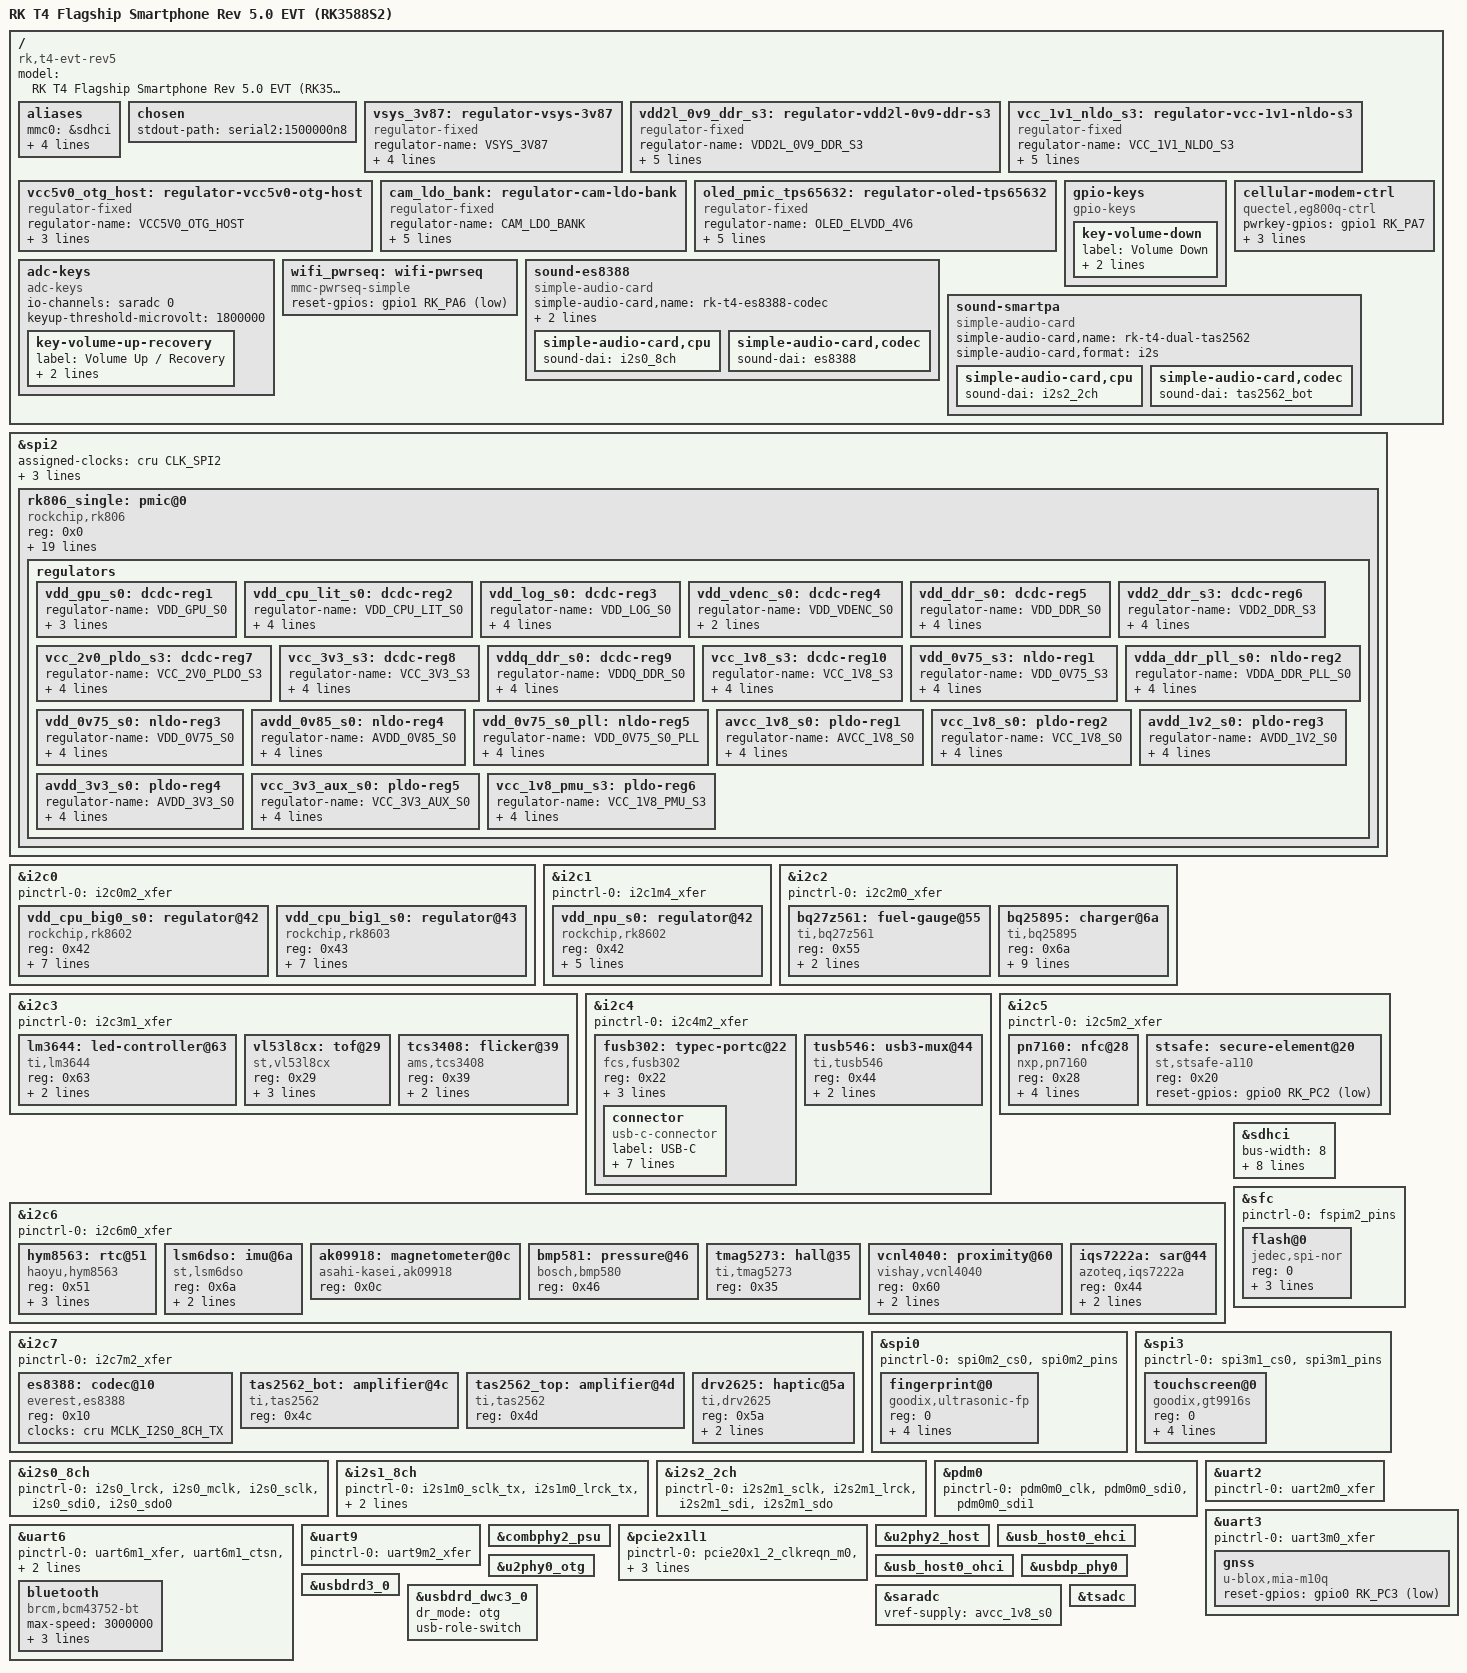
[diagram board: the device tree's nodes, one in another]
// SPDX-License-Identifier: (GPL-2.0+ OR MIT)
/*
 * RK T4 Flagship Smartphone — Rev 5.0 True EVT Linux Device Tree
 * Auto-generated directly from hardware/rk_t4_netlist.json + rk3588s2_1253.json
 * ZERO manual pin guessing: every ball, GPIO bank/pin, mux group, and I2C address
 * is locked 1:1 to the DRC-clean 14L Mainboard + 8L RF Mezzanine PCBs.
 *
 * SoC: Rockchip RK3588S2 (FCCSP1253L, 16GB LPDDR5X-6400, 256GB eMMC 5.1 HS400)
 */

/dts-v1/;

#include <dt-bindings/gpio/gpio.h>
#include <dt-bindings/input/input.h>
#include <dt-bindings/interrupt-controller/irq.h>
#include <dt-bindings/pinctrl/rockchip.h>
#include <dt-bindings/usb/pd.h>
#include "rk3588s.dtsi"

/ {
	model = "RK T4 Flagship Smartphone Rev 5.0 EVT (RK3588S2)";
	compatible = "rk,t4-evt-rev5", "rockchip,rk3588s";

	aliases {
		mmc0 = &sdhci;
		serial2 = &uart2;
		serial3 = &uart3;
		serial6 = &uart6;
		serial9 = &uart9;
	};

	chosen {
		stdout-path = "serial2:1500000n8"; /* U101.AH39 [I2S1_MCLK_M1/JTAG_TCK_M2/I2C1_SCL_M0/UART2_TX_M0/PCIE20X1_1_CLKREQN_M0/GPIO0_B5_d] / U101.AH40 [I2S1_SCLK_TX_M1/JTAG_TMS_M2/I2C1_SDA_M0/UART2_RX_M0/PCIE20X1_1_WAKEN_M0/GPIO0_B6_d] */
	};

	/* Main Battery System Supply (6000mAh 1S2P Si-C via TI BQ25895RTWR NVDC) */
	vsys_3v87: regulator-vsys-3v87 {
		compatible = "regulator-fixed";
		regulator-name = "VSYS_3V87";
		regulator-always-on;
		regulator-boot-on;
		regulator-min-microvolt = <3870000>;
		regulator-max-microvolt = <3870000>;
	};

	/* Dedicated Silergy SY8089AAAC U211 (R211=49.9K / R212=100K -> 0.8994V LPDDR5X VDD2L) */
	vdd2l_0v9_ddr_s3: regulator-vdd2l-0v9-ddr-s3 {
		compatible = "regulator-fixed";
		regulator-name = "VDD2L_0V9_DDR_S3";
		regulator-always-on;
		regulator-boot-on;
		regulator-min-microvolt = <900000>;
		regulator-max-microvolt = <900000>;
		vin-supply = <&vsys_3v87>;
	};

	/* Dedicated Silergy SY8089AAAC U212 (R213=100K / R214=120K -> 1.100V RK806 NLDO Pre-Reg) */
	vcc_1v1_nldo_s3: regulator-vcc-1v1-nldo-s3 {
		compatible = "regulator-fixed";
		regulator-name = "VCC_1V1_NLDO_S3";
		regulator-always-on;
		regulator-boot-on;
		regulator-min-microvolt = <1100000>;
		regulator-max-microvolt = <1100000>;
		vin-supply = <&vsys_3v87>;
	};

	/* TI TPS61022RWUR U210 (R235=732K / R236=100K -> 4.992V USB-C OTG/VCONN Boost) */
	vcc5v0_otg_host: regulator-vcc5v0-otg-host {
		compatible = "regulator-fixed";
		regulator-name = "VCC5V0_OTG_HOST";
		regulator-min-microvolt = <5000000>;
		regulator-max-microvolt = <5000000>;
		vin-supply = <&vsys_3v87>;
	};

	/* SG Micro SGM2036 Discrete Camera RF LDO Bank (U401A..G, U403A..E) */
	cam_ldo_bank: regulator-cam-ldo-bank {
		compatible = "regulator-fixed";
		regulator-name = "CAM_LDO_BANK";
		regulator-min-microvolt = <2800000>;
		regulator-max-microvolt = <2800000>;
		enable-active-high;
		gpio = <&gpio4 RK_PB1 GPIO_ACTIVE_HIGH>; /* U101.AU22 (GPIO4_B1_u) */
		vin-supply = <&vsys_3v87>;
	};

	/* TI TPS65632RTER U501 Triple AMOLED PMIC (+4.6V / -4.0V / +7.7V, SWIRE CTRL) */
	oled_pmic_tps65632: regulator-oled-tps65632 {
		compatible = "regulator-fixed";
		regulator-name = "OLED_ELVDD_4V6";
		regulator-min-microvolt = <4600000>;
		regulator-max-microvolt = <4600000>;
		enable-active-high;
		gpio = <&gpio3 RK_PC1 GPIO_ACTIVE_HIGH>; /* U101.AW38 (GPIO3_C1_d) */
		/* SWIRE single-wire brightness/ELVSS control: U101.AV37 [ETH1_REFCLKO_25M/MIPI_CAMERA1_CLK_M1/I2C4_SCL_M0/GPIO3_A6_d] */
		vin-supply = <&vsys_3v87>;
	};

	/* Side Tactile Keys (Vol- GPIO + Vol+ Recovery SARADC_IN0) */
	gpio-keys {
		compatible = "gpio-keys";
		key-volume-down {
			label = "Volume Down";
			linux,code = <KEY_VOLUMEDOWN>;
			gpios = <&gpio4 RK_PD3 GPIO_ACTIVE_LOW>; /* U101.AT1 (GPIO4_D3_u) */
		};
	};

	adc-keys {
		compatible = "adc-keys";
		io-channels = <&saradc 0>; /* U101.AW15 [SARADC_IN0_BOOT] */
		io-channel-names = "buttons";
		keyup-threshold-microvolt = <1800000>;
		key-volume-up-recovery {
			label = "Volume Up / Recovery";
			linux,code = <KEY_VOLUMEUP>;
			press-threshold-microvolt = <17000>;
		};
	};

	/* Wi-Fi 6E AP6275P Power Sequence (3.3V VBAT <= 3.8V max!) */
	wifi_pwrseq: wifi-pwrseq {
		compatible = "mmc-pwrseq-simple";
		reset-gpios = <&gpio1 RK_PA6 GPIO_ACTIVE_LOW>; /* U101.D39 (GPIO1_A6_d) */
	};

	/* Cellular Modem Quectel EG800Q-EU Control Interface (Open-Drain BSS138 Q701/Q702) */
	cellular-modem-ctrl {
		compatible = "quectel,eg800q-ctrl";
		pwrkey-gpios = <&gpio1 RK_PA7 GPIO_ACTIVE_HIGH>; /* U101.H38 (GPIO1_A7_u) */
		reset-gpios = <&gpio1 RK_PB0 GPIO_ACTIVE_HIGH>; /* U101.H39 (GPIO1_B0_u) */
		status-gpios = <&gpio0 RK_PD4 GPIO_ACTIVE_HIGH>; /* U101.AL39 (GPIO0_D4_u) */
		net-status-gpios = <&gpio3 RK_PB0 GPIO_ACTIVE_HIGH>; /* U101.AR39 (GPIO3_B0_u) */
	};

	/* Audio Routing: ES8388 Codec (I2S0) + Dual TAS2562 SmartPA (I2S2_M1) + 3-Mic ANC (PDM0_M0) */
	sound-es8388 {
		compatible = "simple-audio-card";
		simple-audio-card,name = "rk-t4-es8388-codec";
		simple-audio-card,format = "i2s";
		simple-audio-card,mclk-fs = <256>;
		simple-audio-card,cpu { sound-dai = <&i2s0_8ch>; };
		simple-audio-card,codec { sound-dai = <&es8388>; };
	};

	sound-smartpa {
		compatible = "simple-audio-card";
		simple-audio-card,name = "rk-t4-dual-tas2562";
		simple-audio-card,format = "i2s";
		simple-audio-card,cpu { sound-dai = <&i2s2_2ch>; };
		simple-audio-card,codec { sound-dai = <&tas2562_bot>; };
	};
};

/* ============================================================================
 * PRIMARY MASTER PMIC: ROCKCHIP RK806-1 ON SPI2_M2 (U101.W40/Y39/W39/Y38)
 * ============================================================================ */
&spi2 {
	status = "okay";
	assigned-clocks = <&cru CLK_SPI2>;
	assigned-clock-rates = <200000000>;
	pinctrl-names = "default";
	pinctrl-0 = <&spi2m2_cs0 &spi2m2_pins>;
	num-cs = <1>;

	rk806_single: pmic@0 {
		compatible = "rockchip,rk806";
		reg = <0x0>;
		spi-max-frequency = <1000000>;
		interrupt-parent = <&gpio0>;
		interrupts = <RK_PA7 IRQ_TYPE_LEVEL_LOW>; /* U101.W42 [PMIC_INT_L/GPIO0_A7_u] */
		system-power-controller;
		vcc1-supply = <&vsys_3v87>;
		vcc2-supply = <&vsys_3v87>;
		vcc3-supply = <&vsys_3v87>;
		vcc4-supply = <&vsys_3v87>;
		vcc5-supply = <&vsys_3v87>;
		vcc6-supply = <&vsys_3v87>;
		vcc7-supply = <&vsys_3v87>;
		vcc8-supply = <&vsys_3v87>;
		vcc9-supply = <&vsys_3v87>;
		vcc10-supply = <&vsys_3v87>;
		vcc11-supply = <&vcc_2v0_pldo_s3>;
		vcc12-supply = <&vsys_3v87>;
		vcc13-supply = <&vcc_1v1_nldo_s3>;
		vcc14-supply = <&vcc_1v1_nldo_s3>;
		vcca-supply = <&vsys_3v87>;

		regulators {
			vdd_gpu_s0: dcdc-reg1 {
				regulator-name = "VDD_GPU_S0";
				regulator-min-microvolt = <550000>;
				regulator-max-microvolt = <950000>;
				regulator-enable-ramp-delay = <400>;
			};
			vdd_cpu_lit_s0: dcdc-reg2 {
				regulator-name = "VDD_CPU_LIT_S0";
				regulator-always-on;
				regulator-boot-on;
				regulator-min-microvolt = <550000>;
				regulator-max-microvolt = <950000>;
			};
			vdd_log_s0: dcdc-reg3 {
				regulator-name = "VDD_LOG_S0";
				regulator-always-on;
				regulator-boot-on;
				regulator-min-microvolt = <675000>;
				regulator-max-microvolt = <850000>;
			};
			vdd_vdenc_s0: dcdc-reg4 {
				regulator-name = "VDD_VDENC_S0";
				regulator-min-microvolt = <550000>;
				regulator-max-microvolt = <950000>;
			};
			vdd_ddr_s0: dcdc-reg5 {
				regulator-name = "VDD_DDR_S0";
				regulator-always-on;
				regulator-boot-on;
				regulator-min-microvolt = <675000>;
				regulator-max-microvolt = <900000>;
			};
			vdd2_ddr_s3: dcdc-reg6 {
				regulator-name = "VDD2_DDR_S3";
				regulator-always-on;
				regulator-boot-on;
				regulator-min-microvolt = <1050000>;
				regulator-max-microvolt = <1050000>;
			};
			vcc_2v0_pldo_s3: dcdc-reg7 {
				regulator-name = "VCC_2V0_PLDO_S3";
				regulator-always-on;
				regulator-boot-on;
				regulator-min-microvolt = <2000000>;
				regulator-max-microvolt = <2000000>;
			};
			vcc_3v3_s3: dcdc-reg8 {
				regulator-name = "VCC_3V3_S3";
				regulator-always-on;
				regulator-boot-on;
				regulator-min-microvolt = <3300000>;
				regulator-max-microvolt = <3300000>;
			};
			vddq_ddr_s0: dcdc-reg9 {
				regulator-name = "VDDQ_DDR_S0";
				regulator-always-on;
				regulator-boot-on;
				regulator-min-microvolt = <500000>;
				regulator-max-microvolt = <500000>;
			};
			vcc_1v8_s3: dcdc-reg10 {
				regulator-name = "VCC_1V8_S3";
				regulator-always-on;
				regulator-boot-on;
				regulator-min-microvolt = <1800000>;
				regulator-max-microvolt = <1800000>;
			};
			vdd_0v75_s3: nldo-reg1 {
				regulator-name = "VDD_0V75_S3";
				regulator-always-on;
				regulator-boot-on;
				regulator-min-microvolt = <750000>;
				regulator-max-microvolt = <750000>;
			};
			vdda_ddr_pll_s0: nldo-reg2 {
				regulator-name = "VDDA_DDR_PLL_S0";
				regulator-always-on;
				regulator-boot-on;
				regulator-min-microvolt = <850000>;
				regulator-max-microvolt = <850000>;
			};
			vdd_0v75_s0: nldo-reg3 {
				regulator-name = "VDD_0V75_S0";
				regulator-always-on;
				regulator-boot-on;
				regulator-min-microvolt = <750000>;
				regulator-max-microvolt = <750000>;
			};
			avdd_0v85_s0: nldo-reg4 {
				regulator-name = "AVDD_0V85_S0";
				regulator-always-on;
				regulator-boot-on;
				regulator-min-microvolt = <850000>;
				regulator-max-microvolt = <850000>;
			};
			vdd_0v75_s0_pll: nldo-reg5 {
				regulator-name = "VDD_0V75_S0_PLL";
				regulator-always-on;
				regulator-boot-on;
				regulator-min-microvolt = <750000>;
				regulator-max-microvolt = <750000>;
			};
			avcc_1v8_s0: pldo-reg1 {
				regulator-name = "AVCC_1V8_S0";
				regulator-always-on;
				regulator-boot-on;
				regulator-min-microvolt = <1800000>;
				regulator-max-microvolt = <1800000>;
			};
			vcc_1v8_s0: pldo-reg2 {
				regulator-name = "VCC_1V8_S0";
				regulator-always-on;
				regulator-boot-on;
				regulator-min-microvolt = <1800000>;
				regulator-max-microvolt = <1800000>;
			};
			avdd_1v2_s0: pldo-reg3 {
				regulator-name = "AVDD_1V2_S0";
				regulator-always-on;
				regulator-boot-on;
				regulator-min-microvolt = <1200000>;
				regulator-max-microvolt = <1200000>;
			};
			avdd_3v3_s0: pldo-reg4 {
				regulator-name = "AVDD_3V3_S0";
				regulator-always-on;
				regulator-boot-on;
				regulator-min-microvolt = <3300000>;
				regulator-max-microvolt = <3300000>;
			};
			vcc_3v3_aux_s0: pldo-reg5 {
				regulator-name = "VCC_3V3_AUX_S0";
				regulator-always-on;
				regulator-boot-on;
				regulator-min-microvolt = <3300000>;
				regulator-max-microvolt = <3300000>;
			};
			vcc_1v8_pmu_s3: pldo-reg6 {
				regulator-name = "VCC_1V8_PMU_S3";
				regulator-always-on;
				regulator-boot-on;
				regulator-min-microvolt = <1800000>;
				regulator-max-microvolt = <1800000>;
			};
		};
	};
};

/* ============================================================================
 * ALL 8 HARDWARE I2C BUSES (ZERO PIN-MUX OVERLAP, ZERO 7-BIT ADDRESS COLLISIONS!)
 * ============================================================================ */
/* I2C0_M2: U101.AH41 [I2S1_SDO0_M1/CPU_BIG0_AVS/I2C0_SCL_M2/UART0_CTSN/UART1_TX_M2/SPI0_CS0_M0/HDMI_TX0_CEC_M1/GPIO0_D1_u] / U101.AG41 [I2S1_SDO1_M1/I2C0_SDA_M2/UART1_RX_M2/SPI3_MOSI_M2/GPIO0_D2_u] */
&i2c0 {
	status = "okay";
	pinctrl-names = "default";
	pinctrl-0 = <&i2c0m2_xfer>;

	vdd_cpu_big0_s0: regulator@42 {
		compatible = "rockchip,rk8602";
		reg = <0x42>;
		regulator-name = "VDD_CPU_BIG0_S0";
		regulator-always-on;
		regulator-boot-on;
		regulator-min-microvolt = <550000>;
		regulator-max-microvolt = <1050000>;
		fcs,suspend-voltage-selector = <1>;
		vin-supply = <&vsys_3v87>;
	};

	vdd_cpu_big1_s0: regulator@43 {
		compatible = "rockchip,rk8603";
		reg = <0x43>;
		regulator-name = "VDD_CPU_BIG1_S0";
		regulator-always-on;
		regulator-boot-on;
		regulator-min-microvolt = <550000>;
		regulator-max-microvolt = <1050000>;
		fcs,suspend-voltage-selector = <1>;
		vin-supply = <&vsys_3v87>;
	};
};

/* I2C1_M4: U101.P40 [I2S0_SDO3/I2S0_SDI2/PDM0_SDI2_M0/I2C1_SCL_M4/UART4_TX_M0/PWM0_M1/SPI1_CLK_M2/GPIO1_D2_d] / U101.R39 [I2S0_SDI1/PDM0_SDI3_M0/I2C1_SDA_M4/UART4_RX_M0/PWM1_M1/SPI1_CS0_M2/GPIO1_D3_d] */
&i2c1 {
	status = "okay";
	pinctrl-names = "default";
	pinctrl-0 = <&i2c1m4_xfer>;

	vdd_npu_s0: regulator@42 {
		compatible = "rockchip,rk8602";
		reg = <0x42>;
		regulator-name = "VDD_NPU_S0";
		regulator-min-microvolt = <550000>;
		regulator-max-microvolt = <950000>;
		fcs,suspend-voltage-selector = <1>;
		vin-supply = <&vsys_3v87>;
	};
};

/* I2C2_M0: U101.AK39 [I2S1_LRCK_TX_M1/PWM0_M0/I2C2_SCL_M0/SPI0_CS1_M0/PCIE20X1_1_PERSTN_M0/GPIO0_B7_d] / U101.AM40 [I2S1_SCLK_RX_M1/PDM0_CLK0_M1/PWM1_M0/I2C2_SDA_M0/SPI0_MOSI_M0/GPIO0_C0_d] */
&i2c2 {
	status = "okay";
	pinctrl-names = "default";
	pinctrl-0 = <&i2c2m0_xfer>;

	bq27z561: fuel-gauge@55 {
		compatible = "ti,bq27z561";
		reg = <0x55>;
		interrupt-parent = <&gpio4>;
		interrupts = <RK_PD5 IRQ_TYPE_EDGE_FALLING>; /* U101.AR1 [SDMMC_CLK/PDM1_CLK0_M0/TEST_CLKOUT_M0/MCU_JTAG_TMS_M0/UART5_TX_M0/GPIO4_D5_d] */
	};

	bq25895: charger@6a {
		compatible = "ti,bq25895";
		reg = <0x6a>;
		interrupt-parent = <&gpio4>;
		interrupts = <RK_PD2 IRQ_TYPE_EDGE_FALLING>; /* U101.AV1 [SDMMC_D2/PDM1_SDI1_M0/JTAG_TCK_M0/I2C8_SCL_M0/UART5_CTSN_M0/GPIO4_D2_u] */
		ti,battery-regulation-voltage = <4450000>;
		ti,charge-current = <5000000>;
		ti,termination-current = <256000>;
		ti,precharge-current = <256000>;
		ti,minimum-sys-voltage = <3500000>;
		ti,boost-voltage = <5000000>;
		ti,boost-max-current = <1500000>;
	};
};

/* I2C3_M1: U101.AY34 [GMAC1_PTP_REF_CLK/I2C3_SCL_M1/SPI1_MOSI_M1/GPIO3_B7_d] / U101.AR36 [GMAC1_PPSTRIG/I2C3_SDA_M1/UART7_TX_M1/SPI1_MISO_M1/GPIO3_C0_d] */
&i2c3 {
	status = "okay";
	pinctrl-names = "default";
	pinctrl-0 = <&i2c3m1_xfer>;

	lm3644: led-controller@63 {
		compatible = "ti,lm3644";
		reg = <0x63>;
		enable-gpios = <&gpio3 RK_PB1 GPIO_ACTIVE_HIGH>; /* U101.AV39 (GPIO3_B1_d) */
		strobe-gpios = <&gpio3 RK_PA4 GPIO_ACTIVE_HIGH>; /* U101.AT39 (GPIO3_A4_d) */
	};

	vl53l8cx: tof@29 {
		compatible = "st,vl53l8cx";
		reg = <0x29>;
		interrupt-parent = <&gpio4>;
		interrupts = <RK_PB3 IRQ_TYPE_EDGE_FALLING>; /* U101.AV23 [CIF_VSYNC/BT1120_D9/I2S1_SDO2_M0/PCIE20X1_2_BUTTON_RSTN/I2C7_SDA_M3/UART8_CTSN_M0/PWM15_IR_M1/GPIO4_B3_u] */
		lpn-gpios = <&gpio4 RK_PA4 GPIO_ACTIVE_HIGH>; /* U101.AW19 (GPIO4_A4_d) */
	};

	tcs3408: flicker@39 {
		compatible = "ams,tcs3408";
		reg = <0x39>;
		interrupt-parent = <&gpio4>;
		interrupts = <RK_PB4 IRQ_TYPE_EDGE_FALLING>; /* U101.AV27 [CIF_CLKOUT/BT1120_D10/I2S1_SDO3_M0/DP0_HPDIN_M0/SPDIF0_TX_M1/UART9_TX_M1/PWM11_IR_M1/GPIO4_B4_u] */
	};
};

/* I2C4_M2: U101.AG38 [I2S1_SDI0_M1/GPU_AVS/UART0_TX_M0/I2C4_SCL_M2/PWM4_M0/GPIO0_C5_u] / U101.AL38 [I2S1_LRCK_RX_M1/PDM0_CLK1_M1/PWM2_M0/UART0_RX_M0/I2C4_SDA_M2/DP0_HPDIN_M1/GPIO0_C4_d] */
&i2c4 {
	status = "okay";
	pinctrl-names = "default";
	pinctrl-0 = <&i2c4m2_xfer>;

	fusb302: typec-portc@22 {
		compatible = "fcs,fusb302";
		reg = <0x22>;
		interrupt-parent = <&gpio0>;
		interrupts = <RK_PA4 IRQ_TYPE_LEVEL_LOW>; /* U101.AC38 [SDMMC_DET/GPIO0_A4_u] */
		vbus-supply = <&vcc5v0_otg_host>;
		connector {
			compatible = "usb-c-connector";
			label = "USB-C";
			data-role = "dual";
			power-role = "dual";
			try-power-role = "sink";
			/* Capped safely at 12V (<= 14V max VBUS of TI BQ25895RTWR!) */
			sink-pdos = <PDO_FIXED(5000, 3000, PDO_FIXED_USB_COMM)
			             PDO_FIXED(9000, 3000, PDO_FIXED_USB_COMM)
			             PDO_FIXED(12000, 3000, PDO_FIXED_USB_COMM)>;
			source-pdos = <PDO_FIXED(5000, 1500, PDO_FIXED_USB_COMM)>;
		};
	};

	tusb546: usb3-mux@44 {
		compatible = "ti,tusb546";
		reg = <0x44>;
		orientation-switch;
		mode-switch;
	};
};

/* I2C5_M2: U101.AV18 [CIF_D6/BT1120_D6/I2S1_SDI1_M0/I2C5_SCL_M2/UART3_RX_M2/SPI2_CLK_M1/GPIO4_A6_d] / U101.AW26 [CIF_D7/BT1120_D7/I2S1_SDI2_M0/I2C5_SDA_M2/SPI2_CS0_M1/GPIO4_A7_d] */
&i2c5 {
	status = "okay";
	pinctrl-names = "default";
	pinctrl-0 = <&i2c5m2_xfer>;

	pn7160: nfc@28 {
		compatible = "nxp,pn7160";
		reg = <0x28>;
		interrupt-parent = <&gpio1>;
		interrupts = <RK_PB5 IRQ_TYPE_EDGE_RISING>; /* U101.D40 [UART7_TX_M2/SPI0_CS1_M2/GPIO1_B5_u] */
		enable-gpios = <&gpio0 RK_PC6 GPIO_ACTIVE_HIGH>; /* U101.AH42 (GPIO0_C6_u) */
		firmware-gpios = <&gpio0 RK_PD5 GPIO_ACTIVE_HIGH>; /* U101.AM39 (GPIO0_D5_u) */
	};

	stsafe: secure-element@20 {
		compatible = "st,stsafe-a110";
		reg = <0x20>;
		reset-gpios = <&gpio0 RK_PC2 GPIO_ACTIVE_LOW>; /* U101.AG36 (GPIO0_C2_d) */
	};
};

/* I2C6_M0: U101.AG39 [I2S1_SDI3_M1/PDM0_SDI1_M1/I2C6_SCL_M0/UART1_CTSN_M2/PWM7_IR_M0/SPI3_MISO_M2/GPIO0_D0_d] / U101.AL40 [I2S1_SDI2_M1/PDM0_SDI0_M1/I2C6_SDA_M0/UART1_RTSN_M2/PWM6_M0/SPI0_MISO_M0/GPIO0_C7_d] */
&i2c6 {
	status = "okay";
	pinctrl-names = "default";
	pinctrl-0 = <&i2c6m0_xfer>;

	hym8563: rtc@51 {
		compatible = "haoyu,hym8563";
		reg = <0x51>;
		#clock-cells = <0>;
		clock-output-names = "hym8563_32k";
		interrupt-parent = <&gpio0>;
		interrupts = <RK_PD6 IRQ_TYPE_LEVEL_LOW>; /* U101.AG42 [PMIC_SLEEP6/PDM0_SDI3_M1/GPIO0_D6_d] */
	};

	lsm6dso: imu@6a {
		compatible = "st,lsm6dso";
		reg = <0x6a>;
		interrupt-parent = <&gpio4>;
		interrupts = <RK_PB0 IRQ_TYPE_EDGE_RISING>; /* U101.AW27 [CIF_CLKIN/BT1120_CLKOUT/I2S1_SDI3_M0/I2C6_SDA_M3/UART8_TX_M0/SPI2_CS1_M1/GPIO4_B0_d] */
	};

	ak09918: magnetometer@0c {
		compatible = "asahi-kasei,ak09918";
		reg = <0x0c>;
	};

	bmp581: pressure@46 {
		compatible = "bosch,bmp580";
		reg = <0x46>;
	};

	tmag5273: hall@35 {
		compatible = "ti,tmag5273";
		reg = <0x35>;
	};

	vcnl4040: proximity@60 {
		compatible = "vishay,vcnl4040";
		reg = <0x60>;
		interrupt-parent = <&gpio4>;
		interrupts = <RK_PC1 IRQ_TYPE_LEVEL_LOW>; /* U101.AY26 [BT1120_D15/SPDIF1_TX_M2/PCIE20X1_2_PERSTN_M1/HDMI_TX0_CEC_M0/I2C8_SDA_M3/PWM6_M1/SPI3_CS1_M1/GPIO4_C1_d] */
	};

	iqs7222a: sar@44 {
		compatible = "azoteq,iqs7222a";
		reg = <0x44>;
		interrupt-parent = <&gpio1>;
		interrupts = <RK_PC4 IRQ_TYPE_EDGE_FALLING>; /* U101.U35 [I2S0_SCLK_RX/PDM0_CLK1_M0/I2C2_SDA_M3/PWM11_IR_M2/SPI4_CS1_M0/GPIO1_C4_d] */
	};
};

/* I2C7_M2: U101.AY30 [CIF_D14/I2C7_SCL_M2/UART9_RTSN_M2/SPI0_MOSI_M3/GPIO3_D2_d] / U101.AY31 [CIF_D15/I2C7_SDA_M2/UART9_CTSN_M2/PWM10_M2/SPI0_CLK_M3/GPIO3_D3_d] */
&i2c7 {
	status = "okay";
	pinctrl-names = "default";
	pinctrl-0 = <&i2c7m2_xfer>;

	es8388: codec@10 {
		compatible = "everest,es8388";
		reg = <0x10>;
		#sound-dai-cells = <0>;
		clocks = <&cru MCLK_I2S0_8CH_TX>;
		clock-names = "mclk";
	};

	tas2562_bot: amplifier@4c {
		compatible = "ti,tas2562";
		reg = <0x4c>;
		#sound-dai-cells = <0>;
	};

	tas2562_top: amplifier@4d {
		compatible = "ti,tas2562";
		reg = <0x4d>;
		#sound-dai-cells = <0>;
	};

	drv2625: haptic@5a {
		compatible = "ti,drv2625";
		reg = <0x5a>;
		reset-gpios = <&gpio1 RK_PD0 GPIO_ACTIVE_LOW>; /* U101.U37 (GPIO1_D0_d) */
		trig-gpios = <&gpio4 RK_PD4 GPIO_ACTIVE_HIGH>; /* U101.AU1 (GPIO4_D4_u) */
	};
};

/* ============================================================================
 * STORAGE (eMMC 5.1 HS400 + Winbond W25Q128JWPIQ Quad-SPI NOR FSPI_M2)
 * ============================================================================ */
&sdhci {
	status = "okay";
	bus-width = <8>;
	no-sdio;
	no-sd;
	non-removable;
	max-frequency = <200000000>;
	mmc-hs400-1_8v;
	mmc-hs400-enhanced-strobe;
	vmmc-supply = <&vcc_3v3_s3>;
	vqmmc-supply = <&vcc_1v8_s3>;
};

&sfc {
	status = "okay";
	pinctrl-names = "default";
	pinctrl-0 = <&fspim2_pins>;
	#address-cells = <1>;
	#size-cells = <0>;

	flash@0 {
		compatible = "jedec,spi-nor";
		reg = <0>;
		spi-max-frequency = <104000000>;
		spi-rx-bus-width = <4>;
		spi-tx-bus-width = <1>;
	};
};

/* ============================================================================
 * SPI PERIPHERALS (SPI0_M2 Ultrasonic FP, SPI3_M1 240Hz Touch)
 * ============================================================================ */
&spi0 {
	status = "okay";
	pinctrl-names = "default";
	pinctrl-0 = <&spi0m2_cs0 &spi0m2_pins>;

	fingerprint@0 {
		compatible = "goodix,ultrasonic-fp";
		reg = <0>;
		spi-max-frequency = <12000000>;
		interrupt-parent = <&gpio0>;
		interrupts = <RK_PC1 IRQ_TYPE_EDGE_RISING>; /* U101.AM38 [PMIC_SLEEP3/GPIO0_C1_d] */
		reset-gpios = <&gpio0 RK_PB0 GPIO_ACTIVE_LOW>; /* U101.AC37 (GPIO0_B0_z) */
	};
};

&spi3 {
	status = "okay";
	pinctrl-names = "default";
	pinctrl-0 = <&spi3m1_cs0 &spi3m1_pins>;

	touchscreen@0 {
		compatible = "goodix,gt9916s";
		reg = <0>;
		spi-max-frequency = <12000000>;
		interrupt-parent = <&gpio3>;
		interrupts = <RK_PB4 IRQ_TYPE_EDGE_FALLING>; /* U101.AV35 [GMAC1_TXD1/I2S2_MCLK_M1/UART2_CTSN/GPIO3_B4_u] */
		reset-gpios = <&gpio4 RK_PA3 GPIO_ACTIVE_LOW>; /* U101.AY19 (GPIO4_A3_d) */
	};
};

/* ============================================================================
 * AUDIO INTERFACES (I2S0 ES8388, I2S1_M0 EG800Q VoLTE, I2S2_M1 Dual TAS2562, PDM0_M0)
 * ============================================================================ */
&i2s0_8ch {
	status = "okay";
	pinctrl-names = "default";
	pinctrl-0 = <&i2s0_lrck &i2s0_mclk &i2s0_sclk &i2s0_sdi0 &i2s0_sdo0>;
};

&i2s1_8ch {
	status = "okay";
	pinctrl-names = "default";
	pinctrl-0 = <&i2s1m0_sclk_tx &i2s1m0_lrck_tx &i2s1m0_sdo1 &i2s1m0_sdi0>;
	rockchip,i2s-tx-route = <1 0 2 3>; /* Route VoLTE PCM TX onto SDO1 (U101.AT15)! */
};

&i2s2_2ch {
	status = "okay";
	pinctrl-names = "default";
	pinctrl-0 = <&i2s2m1_sclk &i2s2m1_lrck &i2s2m1_sdi &i2s2m1_sdo>;
};

&pdm0 {
	status = "okay";
	pinctrl-names = "default";
	pinctrl-0 = <&pdm0m0_clk &pdm0m0_sdi0 &pdm0m0_sdi1>;
};

/* ============================================================================
 * UARTS (UART2_M0 Debug, UART3_M0 GNSS MIA-M10Q, UART6_M1 BT 5.4, UART9_M2 EG800Q)
 * ============================================================================ */
&uart2 {
	status = "okay";
	pinctrl-names = "default";
	pinctrl-0 = <&uart2m0_xfer>;
};

&uart3 {
	status = "okay";
	pinctrl-names = "default";
	pinctrl-0 = <&uart3m0_xfer>;

	gnss {
		compatible = "u-blox,mia-m10q";
		reset-gpios = <&gpio0 RK_PC3 GPIO_ACTIVE_LOW>; /* U101.AH38 (GPIO0_C3_d) */
	};
};

&uart6 {
	status = "okay";
	pinctrl-names = "default";
	pinctrl-0 = <&uart6m1_xfer &uart6m1_ctsn &uart6m1_rtsn>;
	uart-has-rtscts;

	bluetooth {
		compatible = "brcm,bcm43752-bt";
		max-speed = <3000000>;
		shutdown-gpios = <&gpio1 RK_PA4 GPIO_ACTIVE_HIGH>; /* U101.G37 (GPIO1_A4_d) */
		device-wakeup-gpios = <&gpio1 RK_PA5 GPIO_ACTIVE_HIGH>; /* U101.M40 (GPIO1_A5_d) */
		host-wakeup-gpios = <&gpio0 RK_PD3 GPIO_ACTIVE_HIGH>; /* U101.AG37 (GPIO0_D3_u) */
	};
};

&uart9 {
	status = "okay";
	pinctrl-names = "default";
	pinctrl-0 = <&uart9m2_xfer>;
};

/* ============================================================================
 * HIGH-SPEED INTERFACES (PCIE20_2 Wi-Fi 6E AP6275P, USB20_HOST0 EG800Q, TYPEC0)
 * ============================================================================ */
&combphy2_psu {
	status = "okay";
};

&pcie2x1l1 {
	status = "okay";
	pinctrl-names = "default";
	pinctrl-0 = <&pcie20x1_2_clkreqn_m0 &pcie20x1_2_waken_m0>;
	reset-gpios = <&gpio3 RK_PD1 GPIO_ACTIVE_HIGH>; /* U101.AY27 (GPIO3_D1_d) */
	vpcie3v3-supply = <&vcc_3v3_s3>;
};

&u2phy2_host { status = "okay"; }; /* USB20_HOST0 -> Quectel EG800Q-EU (REXT U101.AW5=200R) */
&usb_host0_ehci { status = "okay"; };
&usb_host0_ohci { status = "okay"; };

&u2phy0_otg { status = "okay"; }; /* TYPEC0 USB2.0 OTG + VBUSDET (U101.AV10) */
&usbdp_phy0 { status = "okay"; };
&usbdrd3_0 { status = "okay"; };
&usbdrd_dwc3_0 {
	status = "okay";
	dr_mode = "otg";
	usb-role-switch;
};

&saradc {
	status = "okay";
	vref-supply = <&avcc_1v8_s0>;
};

&tsadc {
	status = "okay";
};
